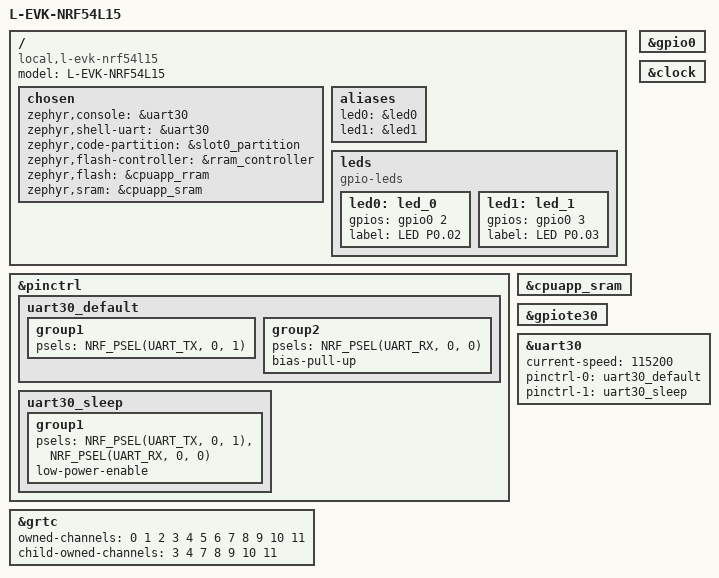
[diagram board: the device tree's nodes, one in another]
/*
 * L-EVK-NRF54L15 custom board, nRF54L15 application core.
 *
 * This board deliberately includes only the SoC description. It does not
 * inherit any nRF54L15 DK board-level devices or pin assignments.
 */

/dts-v1/;

#include <nordic/nrf54l15_cpuapp.dtsi>
#include <zephyr/dt-bindings/gpio/gpio.h>

/ {
	compatible = "local,l-evk-nrf54l15";
	model = "L-EVK-NRF54L15";

	chosen {
		zephyr,console = &uart30;
		zephyr,shell-uart = &uart30;
		zephyr,code-partition = &slot0_partition;
		zephyr,flash-controller = &rram_controller;
		zephyr,flash = &cpuapp_rram;
		zephyr,sram = &cpuapp_sram;
	};

	aliases {
		led0 = &led0;
		led1 = &led1;
	};

	leds {
		compatible = "gpio-leds";

		led0: led_0 {
			gpios = <&gpio0 2 GPIO_ACTIVE_HIGH>;
			label = "LED P0.02";
		};

		led1: led_1 {
			gpios = <&gpio0 3 GPIO_ACTIVE_HIGH>;
			label = "LED P0.03";
		};
	};
};

#include <vendor/nordic/nrf54l15_cpuapp_partition.dtsi>

&pinctrl {
	uart30_default: uart30_default {
		group1 {
			psels = <NRF_PSEL(UART_TX, 0, 1)>;
		};

		group2 {
			psels = <NRF_PSEL(UART_RX, 0, 0)>;
			bias-pull-up;
		};
	};

	uart30_sleep: uart30_sleep {
		group1 {
			psels = <NRF_PSEL(UART_TX, 0, 1)>,
				<NRF_PSEL(UART_RX, 0, 0)>;
			low-power-enable;
		};
	};
};

&cpuapp_sram {
	status = "okay";
};

&grtc {
	/* The application core owns the system timer channels. */
	owned-channels = <0 1 2 3 4 5 6 7 8 9 10 11>;
	child-owned-channels = <3 4 7 8 9 10 11>;
	status = "okay";
};

&gpio0 {
	status = "okay";
};

&gpiote30 {
	status = "okay";
};

&clock {
	status = "okay";
};

&uart30 {
	status = "okay";
	current-speed = <115200>;
	pinctrl-0 = <&uart30_default>;
	pinctrl-1 = <&uart30_sleep>;
	pinctrl-names = "default", "sleep";
};
